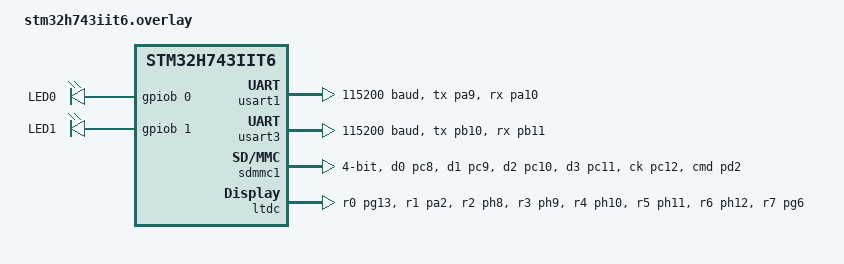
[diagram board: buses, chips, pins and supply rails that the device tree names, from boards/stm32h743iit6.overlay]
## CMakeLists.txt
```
cmake_minimum_required(VERSION 3.20.0)
find_package(Zephyr REQUIRED HINTS $ENV{ZEPHYR_BASE})
project(lvgl_demo)

# ============================================================
# 自行移植的 LVGL 路径 (不使用 Zephyr 内核自带的 lvgl 模块)
# ============================================================
set(LVGL_ROOT_DIR ${CMAKE_CURRENT_SOURCE_DIR}/Middlewares/LVGL)
set(LVGL_SRC_DIR  ${LVGL_ROOT_DIR}/GUI/lvgl/src)
set(LVGL_DEMO_DIR ${LVGL_ROOT_DIR}/GUI_APP/demos)

# --- lib 驱动源文件 ---
file(GLOB LIB_DRIVER_SOURCES CONFIGURE_DEPENDS
  ${CMAKE_CURRENT_SOURCE_DIR}/lib/*.c
)

# --- LVGL 核心源文件 (使用 .mk 中的文件列表思路，显式 glob 各子目录) ---
file(GLOB_RECURSE LVGL_CORE_SOURCES CONFIGURE_DEPENDS
  ${LVGL_SRC_DIR}/core/*.c
  ${LVGL_SRC_DIR}/draw/*.c
  ${LVGL_SRC_DIR}/draw/sw/*.c
  ${LVGL_SRC_DIR}/extra/*.c
  ${LVGL_SRC_DIR}/extra/layouts/flex/*.c
  ${LVGL_SRC_DIR}/extra/layouts/grid/*.c
  ${LVGL_SRC_DIR}/extra/themes/default/*.c
  ${LVGL_SRC_DIR}/extra/themes/basic/*.c
  ${LVGL_SRC_DIR}/extra/themes/mono/*.c
  ${LVGL_SRC_DIR}/extra/widgets/animimg/*.c
  ${LVGL_SRC_DIR}/extra/widgets/calendar/*.c
  ${LVGL_SRC_DIR}/extra/widgets/chart/*.c
  ${LVGL_SRC_DIR}/extra/widgets/colorwheel/*.c
  ${LVGL_SRC_DIR}/extra/widgets/imgbtn/*.c
  ${LVGL_SRC_DIR}/extra/widgets/keyboard/*.c
  ${LVGL_SRC_DIR}/extra/widgets/led/*.c
  ${LVGL_SRC_DIR}/extra/widgets/list/*.c
  ${LVGL_SRC_DIR}/extra/widgets/menu/*.c
  ${LVGL_SRC_DIR}/extra/widgets/meter/*.c
  ${LVGL_SRC_DIR}/extra/widgets/msgbox/*.c
  ${LVGL_SRC_DIR}/extra/widgets/span/*.c
  ${LVGL_SRC_DIR}/extra/widgets/spinbox/*.c
  ${LVGL_SRC_DIR}/extra/widgets/spinner/*.c
  ${LVGL_SRC_DIR}/extra/widgets/tabview/*.c
  ${LVGL_SRC_DIR}/extra/widgets/tileview/*.c
  ${LVGL_SRC_DIR}/extra/widgets/win/*.c
  ${LVGL_SRC_DIR}/extra/others/snapshot/*.c
  ${LVGL_SRC_DIR}/extra/others/monkey/*.c
  ${LVGL_SRC_DIR}/extra/others/gridnav/*.c
  ${LVGL_SRC_DIR}/font/*.c
  ${LVGL_SRC_DIR}/hal/*.c
  ${LVGL_SRC_DIR}/misc/*.c
  ${LVGL_SRC_DIR}/widgets/*.c
)

# --- LVGL demo 源文件 ---
file(GLOB_RECURSE LVGL_DEMO_SOURCES CONFIGURE_DEPENDS
  ${LVGL_DEMO_DIR}/*.c
)

# --- LVGL porting 模板源文件 ---
file(GLOB LVGL_PORTING_SOURCES CONFIGURE_DEPENDS
  ${LVGL_ROOT_DIR}/GUI/lvgl/examples/porting/*.c
)

# --- app 源文件 ---
file(GLOB APP_SOURCES CONFIGURE_DEPENDS
  ${CMAKE_CURRENT_SOURCE_DIR}/app/*.c
)

# --- bootloader app 源文件 (MCUboot 升级相关) ---
file(GLOB BOOTLOADER_APP_SOURCES CONFIGURE_DEPENDS
  ${CMAKE_CURRENT_SOURCE_DIR}/bootloader/app/*.c
)

# --- bootloader lib 源文件 (MCUboot 辅助库) ---
file(GLOB BOOTLOADER_LIB_SOURCES CONFIGURE_DEPENDS
  ${CMAKE_CURRENT_SOURCE_DIR}/bootloader/lib/*.c
)

# --- 应用源文件 ---
target_sources(app PRIVATE
  src/main.c
  src/video_thread.c
  src/led_thread.c
  ${APP_SOURCES}
  ${LIB_DRIVER_SOURCES}
  ${BOOTLOADER_APP_SOURCES}
  ${BOOTLOADER_LIB_SOURCES}
  ${LVGL_CORE_SOURCES}
  ${LVGL_DEMO_SOURCES}
  ${LVGL_PORTING_SOURCES}
)

# --- 头文件路径 ---
target_include_directories(app PRIVATE
  ${CMAKE_CURRENT_SOURCE_DIR}/lib
  ${CMAKE_CURRENT_SOURCE_DIR}/app
  ${CMAKE_CURRENT_SOURCE_DIR}/bootloader/app
  ${CMAKE_CURRENT_SOURCE_DIR}/bootloader/lib
  # LVGL 核心头文件路径 (lvgl.h 内部使用 src/xxx/xxx.h 相对路径)
  ${LVGL_ROOT_DIR}/GUI/lvgl
  # LVGL src 子目录 (部分内部 include 直接写文件名)
  ${LVGL_SRC_DIR}
  ${LVGL_SRC_DIR}/core
  ${LVGL_SRC_DIR}/draw
  ${LVGL_SRC_DIR}/draw/sw
  ${LVGL_SRC_DIR}/extra
  ${LVGL_SRC_DIR}/extra/layouts
  ${LVGL_SRC_DIR}/extra/layouts/flex
  ${LVGL_SRC_DIR}/extra/layouts/grid
  ${LVGL_SRC_DIR}/extra/themes
  ${LVGL_SRC_DIR}/extra/themes/default
  ${LVGL_SRC_DIR}/extra/themes/basic
  ${LVGL_SRC_DIR}/extra/themes/mono
  ${LVGL_SRC_DIR}/extra/widgets
  ${LVGL_SRC_DIR}/extra/widgets/animimg
  ${LVGL_SRC_DIR}/extra/widgets/calendar
  ${LVGL_SRC_DIR}/extra/widgets/chart
  ${LVGL_SRC_DIR}/extra/widgets/colorwheel
  ${LVGL_SRC_DIR}/extra/widgets/imgbtn
  ${LVGL_SRC_DIR}/extra/widgets/keyboard
  ${LVGL_SRC_DIR}/extra/widgets/led
  ${LVGL_SRC_DIR}/extra/widgets/list
  ${LVGL_SRC_DIR}/extra/widgets/menu
  ${LVGL_SRC_DIR}/extra/widgets/meter
  ${LVGL_SRC_DIR}/extra/widgets/msgbox
  ${LVGL_SRC_DIR}/extra/widgets/span
  ${LVGL_SRC_DIR}/extra/widgets/spinbox
  ${LVGL_SRC_DIR}/extra/widgets/spinner
  ${LVGL_SRC_DIR}/extra/widgets/tabview
  ${LVGL_SRC_DIR}/extra/widgets/tileview
  ${LVGL_SRC_DIR}/extra/widgets/win
  ${LVGL_SRC_DIR}/extra/others
  ${LVGL_SRC_DIR}/extra/others/snapshot
  ${LVGL_SRC_DIR}/extra/others/monkey
  ${LVGL_SRC_DIR}/extra/others/gridnav
  ${LVGL_SRC_DIR}/extra/libs
  ${LVGL_SRC_DIR}/extra/libs/bmp
  ${LVGL_SRC_DIR}/extra/libs/fsdrv
  ${LVGL_SRC_DIR}/extra/libs/png
  ${LVGL_SRC_DIR}/extra/libs/gif
  ${LVGL_SRC_DIR}/extra/libs/qrcode
  ${LVGL_SRC_DIR}/extra/libs/sjpg
  ${LVGL_SRC_DIR}/extra/libs/freetype
  ${LVGL_SRC_DIR}/extra/libs/rlottie
  ${LVGL_SRC_DIR}/extra/libs/ffmpeg
  ${LVGL_SRC_DIR}/font
  ${LVGL_SRC_DIR}/hal
  ${LVGL_SRC_DIR}/misc
  ${LVGL_SRC_DIR}/widgets
  # LVGL demo 头文件路径
  ${LVGL_DEMO_DIR}
  ${LVGL_DEMO_DIR}/benchmark
  ${LVGL_DEMO_DIR}/keypad_encoder
  ${LVGL_DEMO_DIR}/music
  ${LVGL_DEMO_DIR}/stress
  ${LVGL_DEMO_DIR}/widgets
  # LVGL porting 模板头文件路径
  ${LVGL_ROOT_DIR}/GUI/lvgl/examples/porting
)
```

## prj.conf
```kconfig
# DEBUG
CONFIG_STM32_ENABLE_DEBUG_SLEEP_STOP=y

# Logging buffer configuration
CONFIG_LOG_BUFFER_SIZE=4096
CONFIG_LOG=y

# Enable FPU support
CONFIG_FPU=y

# DISPLAY/LTDC
CONFIG_DISPLAY=y
CONFIG_STM32_LTDC_RGB565=y
CONFIG_STM32_LTDC_FB_NUM=1

# PRINTK
CONFIG_PRINTK=y

# SDRAM
CONFIG_MEMC=y
CONFIG_MEMC_STM32=y
CONFIG_MEMC_STM32_SDRAM=y

# SDcard
CONFIG_DISK_ACCESS=y
CONFIG_FILE_SYSTEM=y
CONFIG_FAT_FILESYSTEM_ELM=y
CONFIG_FILE_SYSTEM_MKFS=y
CONFIG_LOG=y
CONFIG_SDMMC_STM32_CLOCK_CHECK=n
CONFIG_SDMMC_STM32_HWFC=y

# FATFS
CONFIG_SHELL=y
CONFIG_SHELL_BACKEND_SERIAL=n
CONFIG_FILE_SYSTEM_SHELL=n
CONFIG_FS_FATFS_LFN=y
CONFIG_FS_FATFS_LFN_MODE_HEAP=y
CONFIG_FS_FATFS_MAX_LFN=255
CONFIG_FILE_SYSTEM_MAX_FILE_NAME=255

# STACK 
CONFIG_MAIN_STACK_SIZE=32768

# GPIO
CONFIG_GPIO=y

# ============================================================
# MCUboot Support Configuration
# ============================================================
# Enable MCUboot bootloader support
CONFIG_BOOTLOADER_MCUBOOT=y

# Enable img_mgmt for firmware upgrade management
CONFIG_IMG_MANAGER=y

# Enable MCUboot bootutil library
CONFIG_MCUBOOT_BOOTUTIL_LIB=y

# Flash operation support
CONFIG_FLASH=y
CONFIG_FLASH_PAGE_LAYOUT=y

# Enable MPU to allow Flash write (required for ARM platforms)
CONFIG_MPU_ALLOW_FLASH_WRITE=y

# Use DT code partition (required by MCUboot)
CONFIG_USE_DT_CODE_PARTITION=y

# Enable Flash Map
CONFIG_FLASH_MAP=y

# Enable Stream Flash (for firmware writing)
CONFIG_STREAM_FLASH=y

# Enable CRC checksum
CONFIG_CRC=y

# Heap memory pool size for firmware upgrade
CONFIG_HEAP_MEM_POOL_SIZE=16384

# Software reboot support
CONFIG_REBOOT=y

# ============================================================
# UART OTA Support Configuration
# ============================================================
# Enable UART async API (DMA-based reception)
CONFIG_UART_ASYNC_API=y
CONFIG_SERIAL=y
# Enable DMA support
CONFIG_DMA=y

# DMA must init before UART (default DMA=40, UART=50 -> swap)
CONFIG_DMA_INIT_PRIORITY=30
CONFIG_DMAMUX_STM32_INIT_PRIORITY=31

# Non-cacheable memory for DMA buffers
CONFIG_NOCACHE_MEMORY=y

# Enable ring buffer for UART data buffering
CONFIG_RING_BUFFER=y
```

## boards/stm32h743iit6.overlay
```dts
/ {
	chosen {
		zephyr,console = &usart1;
		zephyr,shell-uart = &usart1;
		zephyr,display = &ltdc;
		/* MCUboot: 指定应用固件所在的代码分区 (板级DTS已定义分区) */
		zephyr,code-partition = &slot0_partition;
	};

	aliases {
		led0 = &user_led0;
		led1 = &user_led1;
	};

	leds {
		compatible = "gpio-leds";
		user_led0: led_0 {
			gpios = <&gpiob 0 GPIO_ACTIVE_HIGH>;
			label = "LED0";
		};
		user_led1: led_1 {
			gpios = <&gpiob 1 GPIO_ACTIVE_HIGH>;
			label = "LED1";
		};
	};

	mdma_irq_reserve {
		compatible = "zephyr,user";
		interrupt-parent = <&nvic>;
		interrupts = <122 0>;
		status = "okay";
	};
};


&usart1 {
	pinctrl-0 = <&usart1_tx_pa9 &usart1_rx_pa10>;
	pinctrl-names = "default";
	current-speed = <115200>;
	status = "okay";
};

&usart3 {
	pinctrl-0 = <&usart3_tx_pb10 &usart3_rx_pb11>;
	pinctrl-names = "default";
	current-speed = <115200>;
	dmas = <&dmamux1 0 46 STM32_DMA_PERIPH_TX>,
	       <&dmamux1 1 45 (STM32_DMA_PERIPH_RX | STM32_DMA_MODE_CYCLIC)>;
	dma-names = "tx", "rx";
	status = "okay";
};

&dma1 {
	status = "okay";
};

&dmamux1 {
	status = "okay";
};

&sdmmc1 {
	status = "okay";
	pinctrl-0 = <&sdmmc1_d0_pc8 &sdmmc1_d1_pc9
	&sdmmc1_d2_pc10 &sdmmc1_d3_pc11
	&sdmmc1_ck_pc12 &sdmmc1_cmd_pd2>;
	pinctrl-names = "default";

	bus-width = <4>;
	clk-div = <2>;
	disk-name = "SD";

};


&ltdc {
	pinctrl-0 = <&ltdc_r0_pg13 &ltdc_r1_pa2 &ltdc_r2_ph8 &ltdc_r3_ph9
	&ltdc_r4_ph10 &ltdc_r5_ph11 &ltdc_r6_ph12 &ltdc_r7_pg6
	&ltdc_g0_pe5 &ltdc_g1_pe6 &ltdc_g2_ph13 &ltdc_g3_ph14
	&ltdc_g4_ph15 &ltdc_g5_pi0 &ltdc_g6_pi1 &ltdc_g7_pi2
	&ltdc_b0_pg14 &ltdc_b1_pg12 &ltdc_b2_pd6 &ltdc_b3_pa8
	&ltdc_b4_pi4 &ltdc_b5_pi5 &ltdc_b6_pi6 &ltdc_b7_pi7
	&ltdc_clk_pg7 &ltdc_hsync_pi10 &ltdc_vsync_pi9 &ltdc_de_pf10>;
	pinctrl-names = "default";
	bl-ctrl-gpios = <&gpiod 12 GPIO_ACTIVE_HIGH>;
	ext-sdram = <&sdram1>;
	clocks = <&rcc STM32_CLOCK(APB3, 3)>, <&rcc STM32_SRC_PLL3_R NO_SEL>;
	status = "okay";

	width = <800>;
	height = <480>;
	pixel-format = <PANEL_PIXEL_FORMAT_RGB_888>;

	display-timings {
		compatible = "zephyr,panel-timing";
		hsync-len = <48>;
		hback-porch = <88>;
		hfront-porch = <40>;
		vsync-len = <3>;
		vback-porch = <32>;
		vfront-porch = <13>;
		hsync-active = <0>;
		vsync-active = <0>;
		de-active = <0>;
		pixelclk-active = <0>;
	};

	def-back-color-red = <0x00>;
	def-back-color-green = <0x00>;
	def-back-color-blue = <0xff>;
};
```

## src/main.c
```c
#include "main.h"
#include "led_thread.h"
#include "video_thread.h"

LOG_MODULE_REGISTER(main, LOG_LEVEL_INF);
/* SD 卡文件系统 */
static FATFS g_sd_fatfs;
static struct fs_mount_t sd_mount = {
    .type = FS_FATFS,
    .mnt_point = "/SD:",
    .fs_data = &g_sd_fatfs,
};

/* SD 卡自动挂载 */
static int sdcard_auto_mount(void)
{
    static const char *disk = "SD";
    int ret;
    for (int i = 0; i < 5; i++)
    {
        ret = disk_access_init(disk);
        if (ret == 0)
            break;
        k_sleep(K_MSEC(100));
    }
    if (ret != 0)
    {
        LOG_ERR("disk_access_init failed (%d)", ret);
        return ret;
    }
    ret = fs_mount(&sd_mount);
    if (ret != 0)
    {
        LOG_ERR("fs_mount failed (%d)", ret);
        return ret;
    }
    LOG_INF("mounted at /SD:");
    return 0;
}

int main(void)
{
    /* ========== 主线程：基础硬件初始化 ========== */
    my_heap_init();
    sdcard_auto_mount();

    /* ========== 创建所有子线程（K_FOREVER 挂起，暂不调度） ========== */

    /* LED闪烁线程 */
    if (led_thread_init() != 0)
    {
        LOG_ERR("led_thread_init failed!");
        return -1;
    }

    /* 视频播放线程 */
    if (video_thread_init() != 0)
    {
        LOG_ERR("video_thread_init failed!");
        return -1;
    }

    /* ========== 统一启动所有子线程，确保同步开始调度 ========== */
    LOG_INF("starting all threads...");
    led_thread_start();
    video_thread_start();

    /* 主线程退出，子线程继续运行 */
    LOG_INF("init done, exiting");
    return 0;
}
```

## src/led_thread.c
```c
#include "led_thread.h"

#include <zephyr/kernel.h>
#include <zephyr/logging/log.h>
#include <zephyr/drivers/gpio.h>
#include <zephyr/devicetree.h>

LOG_MODULE_REGISTER(led_thread, LOG_LEVEL_INF);

/* LED 设备树节点 */
#define LED0_NODE DT_ALIAS(led0)
#define LED1_NODE DT_ALIAS(led1)

/* 线程栈和线程数据结构（栈放置在 DTCM 区域） */
__attribute__((__section__("DTCM"))) static char led_thread_stack[LED_THREAD_STACK_SIZE];
static struct k_thread led_thread_data;
static k_tid_t led_thread_id;

/* LED 设备规格 */
static const struct gpio_dt_spec led0 = GPIO_DT_SPEC_GET(LED0_NODE, gpios);
static const struct gpio_dt_spec led1 = GPIO_DT_SPEC_GET(LED1_NODE, gpios);

/* LED闪烁线程入口函数 */
static void led_thread_entry(void *arg1, void *arg2, void *arg3)
{
    bool led_state = true;

    LOG_INF("started");

    while (1)
    {
        /* 翻转 LED0 和 LED1 */
        led_state = !led_state;

        gpio_pin_set_dt(&led0, led_state ? 1 : 0);
        gpio_pin_set_dt(&led1, led_state ? 1 : 0);

        k_sleep(K_MSEC(LED_BLINK_INTERVAL_MS));
    }
}

/* LED闪烁线程初始化（含GPIO初始化） */
int led_thread_init(void)
{
    /* 初始化 GPIO */
    gpio_pin_configure_dt(&led0, GPIO_OUTPUT_ACTIVE);
    gpio_pin_configure_dt(&led1, GPIO_OUTPUT_ACTIVE);

    /* 创建线程（暂不启动） */
    led_thread_id = k_thread_create(&led_thread_data,
                                    (k_thread_stack_t *)led_thread_stack,
                                    LED_THREAD_STACK_SIZE,
                                    led_thread_entry,
                                    NULL, NULL, NULL,
                                    LED_THREAD_PRIORITY,
                                    0,
                                    K_FOREVER);

    if (led_thread_id == NULL)
    {
        LOG_ERR("create failed");
        return -1;
    }

    LOG_INF("initialized");
    return 0;
}

/* 启动LED闪烁线程 */
void led_thread_start(void)
{
    k_thread_start(led_thread_id);
}

/* 获取线程ID */
k_tid_t led_thread_get_id(void)
{
    return led_thread_id;
}
```

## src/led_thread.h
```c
#ifndef __LED_THREAD_H__
#define __LED_THREAD_H__

#include <zephyr/kernel.h>

/* LED闪烁线程栈大小 */
#define LED_THREAD_STACK_SIZE 1024

/* LED闪烁线程优先级 */
#define LED_THREAD_PRIORITY 7

/* LED闪烁间隔（毫秒） */
#define LED_BLINK_INTERVAL_MS 500

/* 获取LED线程ID */
k_tid_t led_thread_get_id(void);

/* LED闪烁线程初始化（含GPIO初始化，创建线程但不启动） */
int led_thread_init(void);

/* 启动LED闪烁线程 */
void led_thread_start(void);

#endif /* __LED_THREAD_H__ */
```

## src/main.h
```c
#ifndef __MAIN_H_
#define __MAIN_H_

#include <zephyr/kernel.h>
#include <zephyr/logging/log.h>
#include <zephyr/fs/fs.h>
#include <zephyr/storage/disk_access.h>

#include <ff.h>
#include "my_malloc.h"

#endif /* __MAIN_H_ */
```

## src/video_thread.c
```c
#include "video_thread.h"

#include <zephyr/kernel.h>
#include <zephyr/logging/log.h>
#include <zephyr/drivers/display.h>

LOG_MODULE_REGISTER(video_thread, LOG_LEVEL_INF);

#include "lvgl.h"
#include "lv_port_indev_template.h"
#include "lv_port_disp_template.h"

#include "lcd.h"
#include "my_malloc.h"
#include "gt1151q.h"
#include "lvgl_sd_video.h"
#include "lvgl_sd_pic.h"
#include "lvgl_sd_ota.h"
#include "lvgl_uart_ota.h"
#include "lvgl_firmware_upgrade.h"
#include "lvgl_flush_test.h"
#include "jpeg_app.h"

/* 线程栈和线程数据结构（栈放置在 DTCM 区域） */
__attribute__((__section__("DTCM"))) static char video_thread_stack[VIDEO_THREAD_STACK_SIZE];
static struct k_thread video_thread_data;
static k_tid_t video_thread_id;

/* LVGL 定时器（1ms tick） */
static struct k_timer lvgl_tick_timer;

/* 主菜单 screen */
static lv_obj_t *g_main_menu_scr = NULL;

/* LVGL tick 回调 */
static void lvgl_tick_callback(struct k_timer *timer)
{
    lv_tick_inc(1);
}

/* ============================================================
 * 主菜单界面
 * ============================================================ */

static void show_main_menu(void)
{
    /* 删除旧主菜单释放内存 */
    if (g_main_menu_scr != NULL)
    {
        lv_obj_del(g_main_menu_scr);
        g_main_menu_scr = NULL;
    }

    g_main_menu_scr = lv_obj_create(NULL);
    lv_obj_set_style_bg_color(g_main_menu_scr, lv_color_hex(0x101020), 0);
    lv_obj_set_style_pad_all(g_main_menu_scr, 0, 0);

    /* 背景图片 */
    const lv_img_dsc_t *bg_img = lvgl_sd_pic_get_image();
    if (bg_img != NULL && bg_img->data != NULL)
    {
        lv_obj_t *bg = lv_img_create(g_main_menu_scr);
        lv_img_set_src(bg, bg_img);
        lv_obj_set_size(bg, LV_PCT(100), LV_PCT(100));
        lv_obj_align(bg, LV_ALIGN_CENTER, 0, 0);
        lv_obj_set_style_img_opa(bg, LV_OPA_30, 0);
        lv_obj_move_to_index(bg, 0);
    }

    /* 标题 */
    lv_obj_t *title = lv_label_create(g_main_menu_scr);
    lv_label_set_text(title, "Main Menu");
    lv_obj_set_style_text_color(title, lv_color_white(), 0);
    lv_obj_align(title, LV_ALIGN_TOP_MID, 0, 20);

    /* 固件升级界面按钮 (统一入口) */
    lv_obj_t *fw_btn = lv_btn_create(g_main_menu_scr);
    lv_obj_set_size(fw_btn, 200, 50);
    lv_obj_align(fw_btn, LV_ALIGN_CENTER, 0, -60);
    lv_obj_add_event_cb(fw_btn, (lv_event_cb_t)lvgl_firmware_upgrade_start_cb, LV_EVENT_CLICKED, NULL);
    lv_obj_t *fw_lbl = lv_label_create(fw_btn);
    lv_label_set_text(fw_lbl, "Firmware Upgrade");
    lv_obj_center(fw_lbl);

    /* 视频播放界面按钮 */
    lv_obj_t *video_btn = lv_btn_create(g_main_menu_scr);
    lv_obj_set_size(video_btn, 200, 50);
    lv_obj_align(video_btn, LV_ALIGN_CENTER, 0, 0);
    lv_obj_add_event_cb(video_btn, (lv_event_cb_t)lvgl_sd_video_start, LV_EVENT_CLICKED, NULL);
    lv_obj_t *video_lbl = lv_label_create(video_btn);
    lv_label_set_text(video_lbl, "Video Player");
    lv_obj_center(video_lbl);

    /* 刷新测试按钮 */
    lv_obj_t *flush_btn = lv_btn_create(g_main_menu_scr);
    lv_obj_set_size(flush_btn, 200, 50);
    lv_obj_align(flush_btn, LV_ALIGN_CENTER, 0, 60);
    lv_obj_add_event_cb(flush_btn, (lv_event_cb_t)lvgl_flush_test_start, LV_EVENT_CLICKED, NULL);
    lv_obj_t *flush_lbl = lv_label_create(flush_btn);
    lv_label_set_text(flush_lbl, "Flush Test");
    lv_obj_center(flush_lbl);

    lv_scr_load(g_main_menu_scr);
}

/* ============================================================
 * 视频播放线程入口
 * ============================================================ */

static void video_thread_entry(void *arg1, void *arg2, void *arg3)
{
    LOG_INF("started");

    /* 启动 LVGL 1ms tick 定时器 */
    k_timer_start(&lvgl_tick_timer, K_MSEC(1), K_MSEC(1));

    /* 注册视频界面的返回主菜单回调 */
    lvgl_sd_video_set_back_to_menu_cb((lv_event_cb_t)show_main_menu);

    /* 注册 OTA 界面的返回回调 - 返回到统一固件升级界面 */
    lvgl_sd_ota_set_back_to_menu_cb((lv_event_cb_t)lvgl_firmware_upgrade_start_cb);

    /* 注册串口 OTA 界面的返回回调 - 返回到统一固件升级界面 */
    lvgl_uart_ota_set_back_to_menu_cb((lv_event_cb_t)lvgl_firmware_upgrade_start_cb);

    /* 注册统一固件升级界面的返回主菜单回调 */
    lvgl_firmware_upgrade_set_back_to_menu_cb((lv_event_cb_t)show_main_menu);

    /* 注册刷新测试页面的返回主菜单回调 */
    lvgl_flush_test_set_back_cb((lv_event_cb_t)show_main_menu);

    /* 显示主菜单 */
    show_main_menu();

    /* LVGL 主循环 */
    while (1)
    {
        lv_task_handler();
        lvgl_sd_ota_progress_refresh();
        lvgl_uart_ota_progress_refresh();
        k_sleep(K_MSEC(2));
    }
}

/* 视频播放线程初始化（由主线程调用，完成所有资源初始化） */
int video_thread_init(void)
{
    /* LCD 初始化 */
    lcd_init();

    /* 显示开机图片 */
    jpeg_show_first_picture();
    display_blanking_off(disp);

    /* 触摸屏初始化 */
    GT1151Q_Init();

    /* LVGL 初始化 */
    lv_init();
    lv_fs_fatfs_init();
    lv_port_disp_init();
    lv_port_indev_init();

    /* 初始化 LVGL tick 定时器 */
    k_timer_init(&lvgl_tick_timer, lvgl_tick_callback, NULL);

    /* 创建线程（暂不启动） */
    video_thread_id = k_thread_create(&video_thread_data,
                                      (k_thread_stack_t *)video_thread_stack,
                                      VIDEO_THREAD_STACK_SIZE,
                                      video_thread_entry,
                                      NULL, NULL, NULL,
                                      VIDEO_THREAD_PRIORITY,
                                      0,
                                      K_FOREVER);

    if (video_thread_id == NULL)
    {
        LOG_ERR("create failed");
        return -1;
    }

    LOG_INF("initialized");
    return 0;
}

/* 启动视频播放线程 */
void video_thread_start(void)
{
    k_thread_start(video_thread_id);
}

/* 获取线程ID */
k_tid_t video_thread_get_id(void)
{
    return video_thread_id;
}
```

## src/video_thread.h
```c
#ifndef __VIDEO_THREAD_H__
#define __VIDEO_THREAD_H__

#include <zephyr/kernel.h>

/* 视频播放线程栈大小 */
#define VIDEO_THREAD_STACK_SIZE 32768

/* 视频播放线程优先级 */
#define VIDEO_THREAD_PRIORITY 5

/* 获取视频播放线程ID（供外部使用） */
k_tid_t video_thread_get_id(void);

/* 视频播放线程初始化（创建线程，但不启动） */
int video_thread_init(void);

/* 启动视频播放线程 */
void video_thread_start(void);

#endif /* __VIDEO_THREAD_H__ */
```
